# MCU_MCAN1_SS register map
Vendor: Texas Instruments
Peripheral module from a debugger description file (folder J721S2).
Registers are 32-bit, read-only, reset 0x0 unless marked. A register's access mark holds for its fields unless they carry their own. Offsets are as the file gives them; lines under a group give offsets from that group; [hi:lo] are bit positions; {n}, {i} and the like mark numbered series; 'fields as' and 'values as' point back to an identical list; <NAME> marks a mode.

## MCU_MCAN1_SS
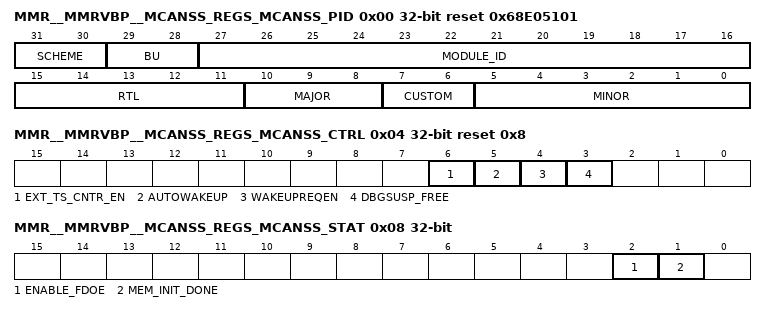
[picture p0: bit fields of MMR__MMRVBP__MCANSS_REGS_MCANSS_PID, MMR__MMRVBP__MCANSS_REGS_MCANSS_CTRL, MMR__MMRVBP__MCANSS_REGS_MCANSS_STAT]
0x00 MMR__MMRVBP__MCANSS_REGS_MCANSS_PID reset 0x68E05101 — The Revision Register contains the major and minor revisions for the module.
  [31:30] SCHEME — PID register scheme
  [29:28] BU — Business Unit: 10 = Processors
  [27:16] MODULE_ID
  [15:11] RTL — RTL revision. Will vary depending on release.
  [10:8] MAJOR — Major revision
  [7:6] CUSTOM
  [5:0] MINOR — Minor revision
0x04 MMR__MMRVBP__MCANSS_REGS_MCANSS_CTRL rw reset 0x8 — The Control Register contains general control bits for the MCANSS
  [6] EXT_TS_CNTR_EN — External TimeStamp Counter Enable
  [5] AUTOWAKEUP — Automatic Wakeup Enable
  [4] WAKEUPREQEN — Wakeup Request Enable
  [3] DBGSUSP_FREE — 0-Honor Debug Suspend, 1-Disregard debug suspend
0x08 MMR__MMRVBP__MCANSS_REGS_MCANSS_STAT — The Status register provide general status bits for the MCANSS
  [2] ENABLE_FDOE — Reflects the value of mcanss_enable_fdoe configuration port x=mcanss_enable_fdoe
  [1] MEM_INIT_DONE — 0:Memory Initialization is in progress, 1:Memory Intialization Done
0x0C MMR__MMRVBP__MCANSS_REGS_MCANSS_ICS wo — Write to clear interrupt bits
  [0] EXT_TS_CNTR_OVFL — External TimeStamp Counter Overflow Interrupt status. Write '1' to clear bits.
0x10 MMR__MMRVBP__MCANSS_REGS_MCANSS_IRS access not given — Read raw interrupt status. Write '1' to set interrupt bits.
  [0] EXT_TS_CNTR_OVFL — External TimeStamp Counter Overflow Interrupt status. (access R/W1TS)
0x14 MMR__MMRVBP__MCANSS_REGS_MCANSS_IECS access not given — Write to clear interrupt enable bits
  [0] EXT_TS_CNTR_OVFL — External TimeStamp Counter Overflow Interrupt. Write '1' to clear bits. (access W1TC)
0x18 MMR__MMRVBP__MCANSS_REGS_MCANSS_IE access not given — Read interrupt Enable
  [0] EXT_TS_CNTR_OVFL — External TimeStamp Counter Overflow Interrupt. (access R/W1TS)
0x1C MMR__MMRVBP__MCANSS_REGS_MCANSS_IES — Read Enabled Interrupts
  [0] EXT_TS_CNTR_OVFL — External TimeStamp Counter Overflow Interrupt
0x20 MMR__MMRVBP__MCANSS_REGS_MCANSS_EOI wo — End of Interrupt Register
  [7:0] EOI — Write with bit position of targeted interrupt. (E.g. Ext TS is bit 0). Upon write, level interrupt will clear and if unserviced interrupt counter > 1 will issue another pulse interrupt
0x24 MMR__MMRVBP__MCANSS_REGS_MCANSS_EXT_TS_PRESCALER rw — External TImeStamp PreScaler
  [23:0] PRESCALER — External Timestamp Prescaler reload value. External Timestamp count rate is host clock rate divided by this value with one exception: a value of 0 has the same effect as 1
0x28 MMR__MMRVBP__MCANSS_REGS_MCANSS_EXT_TS_UNSERVICED_INTR_CNTR — External TImeStamp Unserviced Interrupts Counter
  [4:0] EXT_TS_INTR_CNTR — Number of unserviced rollover interrupts. If >1 an EOI write will issue another pulse interrupt
